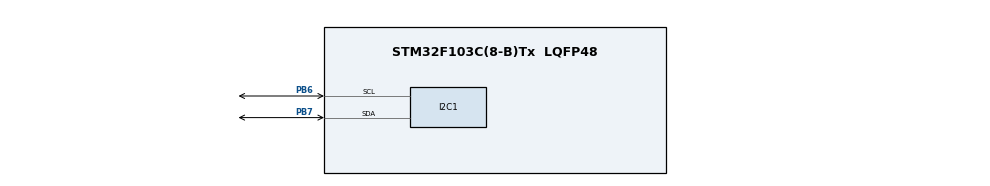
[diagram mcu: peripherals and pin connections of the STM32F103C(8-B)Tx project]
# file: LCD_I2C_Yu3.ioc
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Mcu.Family=STM32F1
Mcu.Name=STM32F103C(8-B)Tx
Mcu.Package=LQFP48
NVIC.PriorityGroup=NVIC_PRIORITYGROUP_4
PA13.Mode=Serial_Wire
PA13.Signal=SYS_JTMS-SWDIO
PA14.Mode=Serial_Wire
PA14.Signal=SYS_JTCK-SWCLK
PB6.Mode=I2C
PB6.Signal=I2C1_SCL
PB7.Mode=I2C
PB7.Signal=I2C1_SDA
PD0-OSC_IN.Mode=HSE-External-Oscillator
PD0-OSC_IN.Signal=RCC_OSC_IN
PD1-OSC_OUT.Mode=HSE-External-Oscillator
PD1-OSC_OUT.Signal=RCC_OSC_OUT
ProjectManager.HeapSize=0x200
ProjectManager.StackSize=0x400
ProjectManager.TargetToolchain=MDK-ARM V5
RCC.APB1Freq_Value=8000000
RCC.APB2Freq_Value=8000000
board=custom

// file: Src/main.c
/* USER CODE BEGIN Header */
/**
  ******************************************************************************
  * @file           : main.c
  * @brief          : Main program body
  ******************************************************************************
  ** This notice applies to any and all portions of this file
  * that are not between comment pairs USER CODE BEGIN and
  * USER CODE END. Other portions of this file, whether
  * inserted by the user or by software development tools
  * are owned by their respective copyright owners.
  *
  * COPYRIGHT(c) 2019 STMicroelectronics
  *
  * Redistribution and use in source and binary forms, with or without modification,
  * are permitted provided that the following conditions are met:
  *   1. Redistributions of source code must retain the above copyright notice,
  *      this list of conditions and the following disclaimer.
  *   2. Redistributions in binary form must reproduce the above copyright notice,
  *      this list of conditions and the following disclaimer in the documentation
  *      and/or other materials provided with the distribution.
  *   3. Neither the name of STMicroelectronics nor the names of its contributors
  *      may be used to endorse or promote products derived from this software
  *      without specific prior written permission.
  *
  * THIS SOFTWARE IS PROVIDED BY THE COPYRIGHT HOLDERS AND CONTRIBUTORS "AS IS"
  * AND ANY EXPRESS OR IMPLIED WARRANTIES, INCLUDING, BUT NOT LIMITED TO, THE
  * IMPLIED WARRANTIES OF MERCHANTABILITY AND FITNESS FOR A PARTICULAR PURPOSE ARE
  * DISCLAIMED. IN NO EVENT SHALL THE COPYRIGHT HOLDER OR CONTRIBUTORS BE LIABLE
  * FOR ANY DIRECT, INDIRECT, INCIDENTAL, SPECIAL, EXEMPLARY, OR CONSEQUENTIAL
  * DAMAGES (INCLUDING, BUT NOT LIMITED TO, PROCUREMENT OF SUBSTITUTE GOODS OR
  * SERVICES; LOSS OF USE, DATA, OR PROFITS; OR BUSINESS INTERRUPTION) HOWEVER
  * CAUSED AND ON ANY THEORY OF LIABILITY, WHETHER IN CONTRACT, STRICT LIABILITY,
  * OR TORT (INCLUDING NEGLIGENCE OR OTHERWISE) ARISING IN ANY WAY OUT OF THE USE
  * OF THIS SOFTWARE, EVEN IF ADVISED OF THE POSSIBILITY OF SUCH DAMAGE.
  *
  ******************************************************************************
  */
/* USER CODE END Header */

#include "main.h"

/* USER CODE BEGIN Includes */
#include "stm32f1xx_hal.h"
#include "lcd.h"
/* USER CODE END Includes */

I2C_HandleTypeDef hi2c1;

void SystemClock_Config(void);
//void Error_Handler(void);
static void MX_GPIO_Init(void);
static void MX_I2C1_Init(void);

/* USER CODE BEGIN 0 */
   volatile uint16_t Adr_i2c = 0x27; // Адрес I2C у-ва
/* USER CODE END 0 */

int main(void)
{
  /* USER CODE BEGIN 1 */
     char str[20];

  /* USER CODE END 1 */

  /* MCU Configuration--------------------------------------------------------*/

  /* Reset of all peripherals, Initializes the Flash interface and the Systick. */
  HAL_Init();

  /* Configure the system clock */
  SystemClock_Config();

  /* Initialize all configured peripherals */
  MX_GPIO_Init();
  MX_I2C1_Init();

  /* USER CODE BEGIN 2 */
	//LCD_ini();        // Производится инициализация по адресу Adr_i2c
    lcd_detect(&hi2c1); // Производится поиск адреса и инициализация у-ва (LCD_ini()). Найденный адрес записывается в Adr_i2c
    // Пример
		HAL_Delay (10);
		LCD_ini();
	sprintf(str,"Stm32F103C8");
	LCD_String(str);
	HAL_Delay(2000);
	LCD_Clear();
	LCD_SetPos(2, 0);
	LCD_SendChar('s');
    HAL_Delay(700);
	LCD_SetPos(3, 0);
	LCD_SendChar('t');
    HAL_Delay(700);
	LCD_SetPos(4, 0);
	LCD_SendChar('m');
    HAL_Delay(700);
    sprintf(str,"32F103C8");
    LCD_String(str);
	HAL_Delay(2000);
  /* USER CODE END 2 */

  /* Infinite loop */
  /* USER CODE BEGIN WHILE */
  const uint32_t Diskreta = 500;
  uint32_t tickstart = HAL_GetTick();
  uint32_t tic_tek = HAL_GetTick();
  uint32_t t_tek;
  while (1)
  {
      if(HAL_GetTick() >= tic_tek)
        {
          t_tek = (tic_tek - tickstart)/1000; // в сек
          tic_tek += Diskreta;
          sprintf (str, "%01i:%02i:%02i  0:00:00", t_tek / 3600, t_tek % 3600 / 60, t_tek % 60);
          LCD_SetPos(0, 1);
          LCD_String(str);
        }
    /* USER CODE END WHILE */

  }
}

void SystemClock_Config(void)
{
  RCC_OscInitTypeDef RCC_OscInitStruct = {0};
  RCC_ClkInitTypeDef RCC_ClkInitStruct = {0};

  /**Initializes the CPU, AHB and APB busses clocks
  */
  RCC_OscInitStruct.OscillatorType = RCC_OSCILLATORTYPE_HSI;
  RCC_OscInitStruct.HSIState = RCC_HSI_ON;
  RCC_OscInitStruct.HSICalibrationValue = RCC_HSICALIBRATION_DEFAULT;
  RCC_OscInitStruct.PLL.PLLState = RCC_PLL_NONE;
  if (HAL_RCC_OscConfig(&RCC_OscInitStruct) != HAL_OK)
  {
    Error_Handler();
  }
  /**Initializes the CPU, AHB and APB busses clocks
  */
  RCC_ClkInitStruct.ClockType = RCC_CLOCKTYPE_HCLK|RCC_CLOCKTYPE_SYSCLK
                              |RCC_CLOCKTYPE_PCLK1|RCC_CLOCKTYPE_PCLK2;
  RCC_ClkInitStruct.SYSCLKSource = RCC_SYSCLKSOURCE_HSI;
  RCC_ClkInitStruct.AHBCLKDivider = RCC_SYSCLK_DIV1;
  RCC_ClkInitStruct.APB1CLKDivider = RCC_HCLK_DIV1;
  RCC_ClkInitStruct.APB2CLKDivider = RCC_HCLK_DIV1;

  if (HAL_RCC_ClockConfig(&RCC_ClkInitStruct, FLASH_LATENCY_0) != HAL_OK)
  {
    Error_Handler();
  }
}

static void MX_I2C1_Init(void)
{

  hi2c1.Instance = I2C1;
  hi2c1.Init.ClockSpeed = 100000;
  hi2c1.Init.DutyCycle = I2C_DUTYCYCLE_2;
  hi2c1.Init.OwnAddress1 = 0;
  hi2c1.Init.AddressingMode = I2C_ADDRESSINGMODE_7BIT;
  hi2c1.Init.DualAddressMode = I2C_DUALADDRESS_DISABLE;
  hi2c1.Init.OwnAddress2 = 0;
  hi2c1.Init.GeneralCallMode = I2C_GENERALCALL_DISABLE;
  hi2c1.Init.NoStretchMode = I2C_NOSTRETCH_DISABLE;
  if (HAL_I2C_Init(&hi2c1) != HAL_OK)
  {
    Error_Handler();
  }

}

static void MX_GPIO_Init(void)
{

  /* GPIO Ports Clock Enable */
  __HAL_RCC_GPIOD_CLK_ENABLE();
  __HAL_RCC_GPIOA_CLK_ENABLE();
  __HAL_RCC_GPIOB_CLK_ENABLE();

}

void Error_Handler(void)
{
}

/************************ (C) COPYRIGHT STMicroelectronics *****END OF FILE****/
